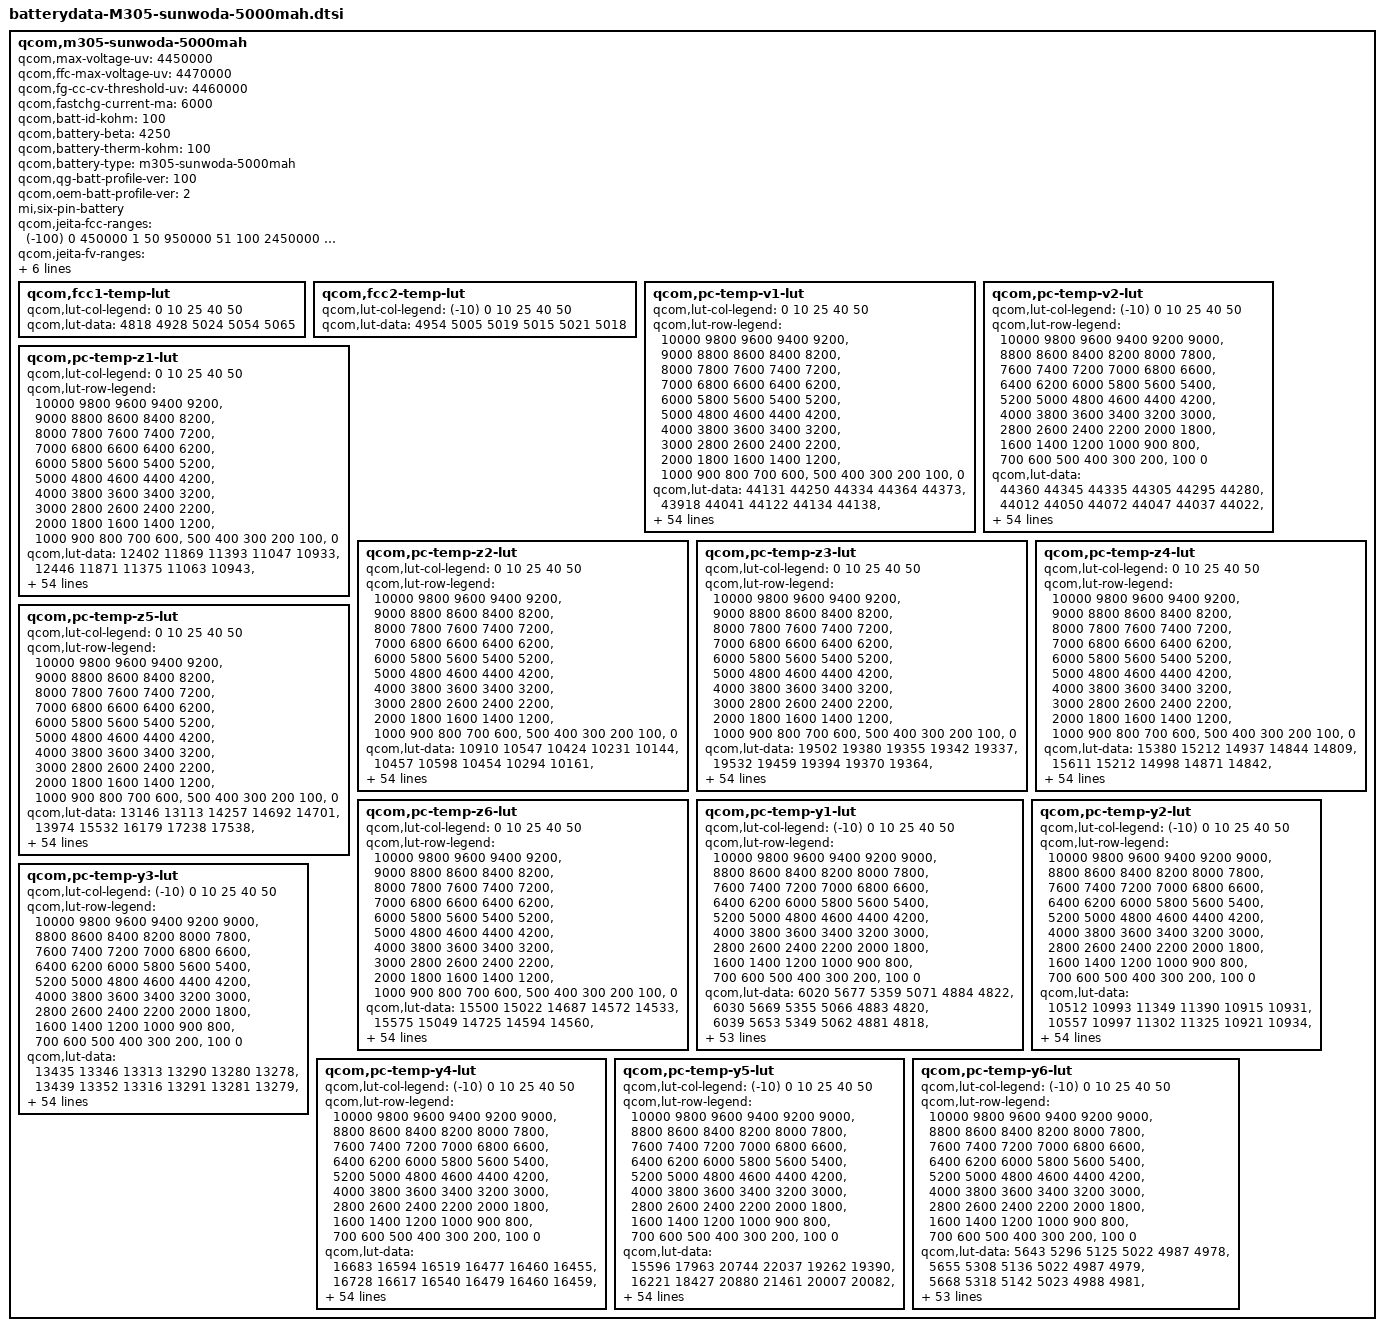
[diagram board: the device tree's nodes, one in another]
/*
 * Copyright (c) 2019, The Linux Foundation. All rights reserved.
 * Copyright (C) 2021 XiaoMi, Inc.
 *
 * This program is free software; you can redistribute it and/or modify
 * it under the terms of the GNU General Public License version 2 and
 * only version 2 as published by the Free Software Foundation.
 *
 * This program is distributed in the hope that it will be useful,
 * but WITHOUT ANY WARRANTY; without even the implied warranty of
 * MERCHANTABILITY or FITNESS FOR A PARTICULAR PURPOSE.  See the
 * GNU General Public License for more details.
 */
/* 4622819_LC_M700_ATL_5160mAH_PM7150B_averaged_Master_May26th2020 */

 qcom,m305-sunwoda-5000mah {
	/* 4916507_LC_M305_5020mAH_PM6150_averaged_MasterSlave_Nov12th2020 */
	qcom,max-voltage-uv = <4450000>;
	qcom,ffc-max-voltage-uv = <4470000>;
	qcom,fg-cc-cv-threshold-uv = <4460000>;
	qcom,fastchg-current-ma = <6000>;
	qcom,batt-id-kohm = <100>;
	qcom,battery-beta = <4250>;
	qcom,battery-therm-kohm = <100>;
	qcom,battery-type = "m305-sunwoda-5000mah";
	qcom,qg-batt-profile-ver = <100>;
	qcom,oem-batt-profile-ver = <2>;
	mi,six-pin-battery;

	qcom,jeita-fcc-ranges = <(-100)  0   450000
                                1   50   950000
				51  100  2450000
				101 150  3900000
				151 480  6000000
				481 580  2450000>;

	qcom,jeita-fv-ranges = <(-100)   0   4450000
                                1   50   4450000
				51  100  4450000
				101 150  4450000
				151 480  4470000
				481 580  4100000>;

	/* COOL = 15 degc, WARM = 48 degC */
	qcom,jeita-soft-thresholds = <0x4621 0x1de6>;
	/* COLD = -10 degC, HOT = 58 degC*/
	qcom,jeita-hard-thresholds = <0x6226 0x15f7>;
	/* COOL hys = 18 degC, WARM hys = 45 degC */
	qcom,jeita-soft-hys-thresholds = <0x4206 0x20b8>;
	qcom,jeita-soft-fcc-ua = <3900000 2450000>;
	qcom,jeita-soft-fv-uv = <4450000 4100000>;

	qcom,fcc1-temp-lut {
		qcom,lut-col-legend = <0 10 25 40 50>;
		qcom,lut-data = <4818 4928 5024 5054 5065>;
	};

	qcom,fcc2-temp-lut {
		qcom,lut-col-legend = <(-10) 0 10 25 40 50>;
		qcom,lut-data = <4954 5005 5019 5015 5021 5018>;
	};

	qcom,pc-temp-v1-lut {
		qcom,lut-col-legend = <0 10 25 40 50>;
		qcom,lut-row-legend = <10000 9800 9600 9400 9200>,
			<9000 8800 8600 8400 8200>,
			<8000 7800 7600 7400 7200>,
			<7000 6800 6600 6400 6200>,
			<6000 5800 5600 5400 5200>,
			<5000 4800 4600 4400 4200>,
			<4000 3800 3600 3400 3200>,
			<3000 2800 2600 2400 2200>,
			<2000 1800 1600 1400 1200>,
			<1000 900 800 700 600>,
			<500 400 300 200 100>,
			<0>;
		qcom,lut-data = <44131 44250 44334 44364 44373>,
			<43918 44041 44122 44134 44138>,
			<43699 43831 43918 43929 43931>,
			<43476 43621 43709 43725 43729>,
			<43246 43406 43495 43515 43519>,
			<43010 43177 43274 43301 43306>,
			<42773 42936 43042 43076 43082>,
			<42533 42693 42801 42837 42844>,
			<42294 42450 42559 42595 42603>,
			<42066 42208 42314 42351 42362>,
			<41848 41973 42071 42108 42121>,
			<41631 41742 41833 41868 41883>,
			<41407 41517 41600 41631 41647>,
			<41183 41294 41371 41399 41415>,
			<40973 41077 41147 41176 41188>,
			<40778 40868 40930 40960 40967>,
			<40589 40665 40722 40750 40754>,
			<40394 40471 40521 40546 40548>,
			<40198 40295 40332 40352 40353>,
			<40015 40122 40161 40179 40178>,
			<39860 39919 39980 40002 40003>,
			<39705 39665 39740 39768 39777>,
			<39498 39423 39466 39480 39497>,
			<39210 39228 39255 39254 39267>,
			<38984 39058 39095 39103 39109>,
			<38875 38930 38960 38975 38978>,
			<38799 38836 38841 38851 38853>,
			<38731 38752 38736 38734 38739>,
			<38671 38664 38637 38628 38633>,
			<38615 38577 38542 38531 38533>,
			<38555 38499 38455 38442 38443>,
			<38495 38428 38380 38365 38361>,
			<38438 38364 38311 38294 38287>,
			<38385 38307 38250 38226 38216>,
			<38337 38256 38197 38161 38147>,
			<38293 38209 38145 38098 38078>,
			<38257 38170 38096 38035 38008>,
			<38213 38128 38045 37973 37936>,
			<38141 38061 37978 37895 37847>,
			<38044 37965 37888 37794 37733>,
			<37934 37855 37782 37681 37608>,
			<37802 37729 37662 37565 37488>,
			<37651 37584 37523 37436 37358>,
			<37473 37406 37355 37263 37186>,
			<37347 37248 37201 37123 37050>,
			<37234 37139 37094 37044 36984>,
			<37193 37107 37066 37011 36953>,
			<37159 37087 37043 36993 36934>,
			<37124 37059 37025 36971 36911>,
			<37075 37018 36977 36910 36839>,
			<36893 36805 36738 36636 36545>,
			<36445 36354 36287 36185 36095>,
			<35858 35760 35697 35598 35506>,
			<35050 34938 34886 34795 34701>,
			<33694 33574 33616 33536 33440>,
			<30000 30000 30000 30000 30000>;
	};

	qcom,pc-temp-v2-lut {
		qcom,lut-col-legend = <(-10) 0 10 25 40 50>;
		qcom,lut-row-legend = <10000 9800 9600 9400 9200 9000>,
			<8800 8600 8400 8200 8000 7800>,
			<7600 7400 7200 7000 6800 6600>,
			<6400 6200 6000 5800 5600 5400>,
			<5200 5000 4800 4600 4400 4200>,
			<4000 3800 3600 3400 3200 3000>,
			<2800 2600 2400 2200 2000 1800>,
			<1600 1400 1200 1000 900 800>,
			<700 600 500 400 300 200>,
			<100 0>;
		qcom,lut-data = <44360 44345 44335 44305 44295 44280>,
			<44012 44050 44072 44047 44037 44022>,
			<43697 43778 43823 43801 43791 43778>,
			<43421 43532 43592 43570 43560 43548>,
			<43181 43313 43379 43355 43345 43335>,
			<42946 43091 43161 43135 43127 43118>,
			<42697 42851 42925 42899 42893 42887>,
			<42448 42606 42681 42657 42652 42648>,
			<42209 42360 42437 42414 42411 42409>,
			<41984 42111 42192 42169 42168 42166>,
			<41756 41867 41949 41927 41927 41925>,
			<41510 41629 41710 41688 41688 41686>,
			<41262 41400 41476 41453 41453 41452>,
			<41049 41183 41245 41222 41223 41222>,
			<40879 40979 41020 40998 40998 40998>,
			<40689 40777 40802 40780 40781 40780>,
			<40395 40578 40596 40571 40573 40572>,
			<40034 40372 40394 40369 40372 40371>,
			<39747 40131 40193 40179 40183 40182>,
			<39530 39844 39993 40002 40006 40005>,
			<39326 39570 39776 39806 39814 39814>,
			<39098 39330 39511 39557 39576 39582>,
			<38868 39110 39241 39295 39329 39341>,
			<38678 38919 39033 39082 39117 39131>,
			<38520 38750 38859 38899 38925 38938>,
			<38390 38596 38706 38742 38764 38775>,
			<38294 38454 38569 38611 38635 38644>,
			<38216 38325 38446 38497 38523 38530>,
			<38146 38210 38334 38390 38418 38423>,
			<38081 38104 38232 38291 38320 38323>,
			<38022 38023 38139 38202 38231 38233>,
			<37961 37967 38051 38121 38154 38155>,
			<37903 37922 37973 38045 38081 38081>,
			<37844 37880 37907 37975 38008 38004>,
			<37786 37842 37850 37909 37934 37926>,
			<37727 37803 37798 37839 37852 37837>,
			<37664 37764 37754 37761 37754 37724>,
			<37598 37721 37710 37679 37649 37606>,
			<37524 37656 37649 37596 37555 37508>,
			<37441 37560 37572 37512 37465 37422>,
			<37348 37446 37478 37422 37370 37331>,
			<37241 37316 37356 37321 37271 37230>,
			<37119 37167 37215 37206 37156 37113>,
			<37007 36995 37053 37062 37009 36958>,
			<36902 36848 36904 36934 36895 36844>,
			<36804 36748 36825 36877 36853 36803>,
			<36756 36716 36792 36859 36843 36792>,
			<36713 36675 36760 36842 36828 36777>,
			<36664 36629 36711 36816 36802 36749>,
			<36611 36552 36622 36746 36718 36653>,
			<36516 36338 36378 36508 36433 36333>,
			<36303 35908 35872 36014 35933 35828>,
			<35864 35265 35199 35382 35289 35175>,
			<35165 34309 34285 34531 34406 34275>,
			<34164 32747 32829 33216 33099 32945>,
			<32424 29203 28284 28221 28318 28327>;
	};

	qcom,pc-temp-z1-lut {
		qcom,lut-col-legend = <0 10 25 40 50>;
		qcom,lut-row-legend = <10000 9800 9600 9400 9200>,
			<9000 8800 8600 8400 8200>,
			<8000 7800 7600 7400 7200>,
			<7000 6800 6600 6400 6200>,
			<6000 5800 5600 5400 5200>,
			<5000 4800 4600 4400 4200>,
			<4000 3800 3600 3400 3200>,
			<3000 2800 2600 2400 2200>,
			<2000 1800 1600 1400 1200>,
			<1000 900 800 700 600>,
			<500 400 300 200 100>,
			<0>;
		qcom,lut-data = <12402 11869 11393 11047 10933>,
			<12446 11871 11375 11063 10943>,
			<12427 11868 11368 11056 10939>,
			<12400 11859 11361 11048 10934>,
			<12383 11847 11353 11042 10930>,
			<12366 11834 11345 11035 10926>,
			<12350 11819 11335 11029 10923>,
			<12327 11803 11321 11022 10920>,
			<12302 11787 11310 11017 10917>,
			<12293 11772 11303 11014 10915>,
			<12292 11762 11297 11011 10914>,
			<12289 11753 11292 11009 10913>,
			<12269 11748 11288 11007 10912>,
			<12235 11746 11286 11006 10912>,
			<12224 11744 11284 11005 10911>,
			<12224 11743 11283 11005 10911>,
			<12224 11739 11283 11005 10911>,
			<12218 11735 11285 11005 10912>,
			<12200 11729 11286 11005 10913>,
			<12190 11723 11288 11006 10914>,
			<12197 11721 11290 11008 10916>,
			<12209 11724 11291 11008 10917>,
			<12213 11728 11292 11008 10918>,
			<12222 11729 11293 11009 10919>,
			<12226 11731 11298 11012 10921>,
			<12222 11733 11304 11016 10923>,
			<12217 11740 11310 11020 10926>,
			<12214 11746 11317 11023 10929>,
			<12214 11747 11322 11027 10932>,
			<12216 11747 11326 11031 10936>,
			<12223 11749 11329 11035 10939>,
			<12231 11756 11333 11038 10942>,
			<12237 11764 11338 11040 10945>,
			<12247 11767 11342 11044 10948>,
			<12256 11769 11346 11049 10952>,
			<12256 11772 11350 11054 10957>,
			<12250 11776 11357 11059 10960>,
			<12246 11780 11366 11064 10964>,
			<12257 11788 11375 11069 10967>,
			<12278 11801 11385 11073 10971>,
			<12292 11809 11394 11078 10974>,
			<12300 11812 11399 11083 10978>,
			<12310 11816 11403 11088 10982>,
			<12328 11834 11411 11091 10984>,
			<12348 11847 11428 11097 10986>,
			<12364 11859 11427 11099 10987>,
			<12358 11862 11430 11101 10987>,
			<12356 11840 11430 11103 10988>,
			<12351 11842 11436 11104 10990>,
			<12345 11856 11440 11110 10993>,
			<12380 11867 11456 11114 10997>,
			<12406 11879 11461 11121 11002>,
			<12406 11890 11471 11130 11010>,
			<12425 11914 11488 11142 11022>,
			<12425 11914 11488 11142 11022>,
			<12425 11914 11488 11142 11022>;
	};

	qcom,pc-temp-z2-lut {
		qcom,lut-col-legend = <0 10 25 40 50>;
		qcom,lut-row-legend = <10000 9800 9600 9400 9200>,
			<9000 8800 8600 8400 8200>,
			<8000 7800 7600 7400 7200>,
			<7000 6800 6600 6400 6200>,
			<6000 5800 5600 5400 5200>,
			<5000 4800 4600 4400 4200>,
			<4000 3800 3600 3400 3200>,
			<3000 2800 2600 2400 2200>,
			<2000 1800 1600 1400 1200>,
			<1000 900 800 700 600>,
			<500 400 300 200 100>,
			<0>;
		qcom,lut-data = <10910 10547 10424 10231 10144>,
			<10457 10598 10454 10294 10161>,
			<10447 10612 10524 10333 10214>,
			<10431 10587 10540 10354 10236>,
			<10411 10549 10514 10345 10225>,
			<10377 10521 10480 10322 10196>,
			<10348 10489 10445 10300 10185>,
			<10326 10461 10405 10270 10184>,
			<10309 10437 10387 10248 10180>,
			<10329 10417 10380 10236 10136>,
			<10450 10405 10377 10228 10067>,
			<10535 10397 10376 10228 10052>,
			<10470 10393 10372 10235 10057>,
			<10349 10410 10373 10237 10066>,
			<10319 10442 10380 10212 10079>,
			<10341 10462 10388 10175 10096>,
			<10371 10475 10393 10162 10103>,
			<10396 10487 10397 10154 10105>,
			<10421 10500 10403 10154 10108>,
			<10439 10514 10409 10166 10130>,
			<10453 10533 10420 10191 10163>,
			<10463 10565 10475 10272 10194>,
			<10463 10586 10573 10451 10239>,
			<10455 10562 10594 10522 10278>,
			<10449 10511 10519 10398 10426>,
			<10456 10498 10455 10264 10602>,
			<10469 10519 10474 10292 10581>,
			<10478 10540 10516 10396 10420>,
			<10483 10545 10527 10434 10286>,
			<10488 10547 10516 10368 10183>,
			<10496 10548 10501 10278 10104>,
			<10505 10547 10483 10213 10077>,
			<10512 10547 10464 10155 10061>,
			<10517 10550 10461 10140 10058>,
			<10522 10560 10474 10153 10078>,
			<10526 10570 10494 10173 10111>,
			<10532 10580 10519 10203 10158>,
			<10540 10590 10550 10251 10221>,
			<10552 10602 10575 10300 10263>,
			<10566 10617 10595 10355 10293>,
			<10569 10626 10612 10395 10309>,
			<10560 10628 10629 10402 10299>,
			<10560 10631 10641 10404 10283>,
			<10596 10643 10631 10451 10310>,
			<10428 10750 10644 10433 10314>,
			<10558 10817 10660 10355 10251>,
			<10661 10800 10650 10343 10246>,
			<10832 10817 10625 10391 10285>,
			<10766 10811 10628 10391 10309>,
			<12908 10884 10655 10437 10362>,
			<13525 10944 10706 10371 10269>,
			<10574 10997 10600 10230 10116>,
			<10307 10938 10577 10181 10065>,
			<10025 10788 10504 10134 10018>,
			<10025 10788 10504 10134 10018>,
			<10025 10788 10504 10134 10018>;
	};

	qcom,pc-temp-z3-lut {
		qcom,lut-col-legend = <0 10 25 40 50>;
		qcom,lut-row-legend = <10000 9800 9600 9400 9200>,
			<9000 8800 8600 8400 8200>,
			<8000 7800 7600 7400 7200>,
			<7000 6800 6600 6400 6200>,
			<6000 5800 5600 5400 5200>,
			<5000 4800 4600 4400 4200>,
			<4000 3800 3600 3400 3200>,
			<3000 2800 2600 2400 2200>,
			<2000 1800 1600 1400 1200>,
			<1000 900 800 700 600>,
			<500 400 300 200 100>,
			<0>;
		qcom,lut-data = <19502 19380 19355 19342 19337>,
			<19532 19459 19394 19370 19364>,
			<19592 19499 19414 19385 19375>,
			<19646 19513 19426 19395 19383>,
			<19665 19521 19435 19401 19389>,
			<19678 19530 19441 19405 19394>,
			<19684 19539 19443 19409 19399>,
			<19685 19543 19444 19413 19403>,
			<19685 19542 19444 19415 19405>,
			<19684 19539 19442 19413 19403>,
			<19683 19536 19440 19409 19398>,
			<19681 19529 19436 19406 19394>,
			<19673 19522 19429 19404 19391>,
			<19660 19516 19425 19401 19389>,
			<19651 19510 19422 19396 19386>,
			<19644 19507 19420 19391 19384>,
			<19636 19505 19417 19388 19381>,
			<19627 19503 19414 19385 19378>,
			<19618 19497 19411 19382 19375>,
			<19613 19490 19408 19377 19369>,
			<19612 19490 19405 19372 19364>,
			<19612 19507 19412 19375 19364>,
			<19615 19520 19426 19387 19368>,
			<19625 19513 19429 19391 19371>,
			<19631 19498 19413 19382 19379>,
			<19627 19493 19400 19371 19390>,
			<19619 19494 19405 19380 19398>,
			<19613 19495 19418 19408 19409>,
			<19608 19500 19428 19419 19413>,
			<19606 19509 19436 19416 19409>,
			<19606 19512 19440 19411 19401>,
			<19607 19510 19438 19404 19394>,
			<19608 19508 19433 19395 19386>,
			<19606 19505 19428 19387 19378>,
			<19604 19500 19422 19381 19369>,
			<19602 19495 19417 19375 19361>,
			<19598 19491 19413 19370 19355>,
			<19593 19488 19409 19365 19349>,
			<19588 19484 19406 19364 19348>,
			<19583 19480 19403 19364 19350>,
			<19577 19476 19400 19364 19353>,
			<19572 19471 19398 19365 19355>,
			<19565 19465 19396 19365 19358>,
			<19551 19461 19392 19370 19363>,
			<19320 19436 19383 19369 19364>,
			<19261 19424 19377 19354 19353>,
			<19261 19421 19372 19353 19351>,
			<19260 19410 19370 19343 19338>,
			<19261 19409 19359 19339 19333>,
			<19257 19392 19355 19336 19330>,
			<19259 19393 19354 19354 19345>,
			<19260 19370 19372 19366 19355>,
			<19262 19347 19368 19366 19356>,
			<19266 19338 19367 19361 19355>,
			<19266 19338 19367 19361 19355>,
			<19266 19338 19367 19361 19355>;
	};

	qcom,pc-temp-z4-lut {
		qcom,lut-col-legend = <0 10 25 40 50>;
		qcom,lut-row-legend = <10000 9800 9600 9400 9200>,
			<9000 8800 8600 8400 8200>,
			<8000 7800 7600 7400 7200>,
			<7000 6800 6600 6400 6200>,
			<6000 5800 5600 5400 5200>,
			<5000 4800 4600 4400 4200>,
			<4000 3800 3600 3400 3200>,
			<3000 2800 2600 2400 2200>,
			<2000 1800 1600 1400 1200>,
			<1000 900 800 700 600>,
			<500 400 300 200 100>,
			<0>;
		qcom,lut-data = <15380 15212 14937 14844 14809>,
			<15611 15212 14998 14871 14842>,
			<15527 15210 14961 14853 14832>,
			<15404 15143 14922 14830 14816>,
			<15300 15040 14881 14808 14799>,
			<15195 14973 14842 14784 14778>,
			<15107 14919 14813 14763 14759>,
			<15041 14875 14788 14744 14742>,
			<14983 14841 14766 14728 14729>,
			<14927 14813 14742 14717 14721>,
			<14866 14790 14726 14708 14716>,
			<14827 14771 14720 14702 14712>,
			<14816 14756 14717 14699 14708>,
			<14809 14747 14714 14695 14705>,
			<14800 14739 14710 14692 14702>,
			<14781 14736 14705 14690 14699>,
			<14766 14734 14702 14686 14696>,
			<14769 14733 14699 14683 14693>,
			<14780 14730 14696 14679 14690>,
			<14786 14728 14693 14673 14683>,
			<14774 14730 14690 14669 14677>,
			<14758 14757 14710 14686 14691>,
			<14770 14790 14759 14744 14754>,
			<14847 14822 14790 14777 14787>,
			<14902 14854 14811 14784 14774>,
			<14899 14861 14822 14788 14752>,
			<14890 14842 14810 14773 14733>,
			<14879 14818 14781 14728 14708>,
			<14862 14799 14758 14704 14695>,
			<14845 14781 14740 14698 14691>,
			<14831 14770 14727 14694 14689>,
			<14818 14765 14723 14691 14685>,
			<14809 14761 14720 14688 14681>,
			<14803 14760 14718 14686 14677>,
			<14798 14758 14717 14684 14673>,
			<14791 14757 14717 14682 14671>,
			<14784 14753 14716 14682 14670>,
			<14777 14748 14715 14682 14670>,
			<14771 14745 14715 14684 14671>,
			<14764 14742 14716 14693 14685>,
			<14756 14737 14717 14700 14696>,
			<14743 14724 14710 14694 14692>,
			<14727 14709 14697 14686 14684>,
			<14709 14697 14691 14686 14689>,
			<14868 14673 14674 14676 14681>,
			<14910 14657 14657 14659 14654>,
			<14907 14652 14652 14654 14646>,
			<14899 14652 14642 14648 14644>,
			<14895 14645 14637 14633 14628>,
			<14889 14659 14636 14626 14621>,
			<14887 14663 14655 14647 14658>,
			<14897 14694 14647 14652 14666>,
			<14901 14724 14652 14657 14673>,
			<14908 14740 14656 14665 14677>,
			<14908 14740 14656 14665 14677>,
			<14908 14740 14656 14665 14677>;
	};

	qcom,pc-temp-z5-lut {
		qcom,lut-col-legend = <0 10 25 40 50>;
		qcom,lut-row-legend = <10000 9800 9600 9400 9200>,
			<9000 8800 8600 8400 8200>,
			<8000 7800 7600 7400 7200>,
			<7000 6800 6600 6400 6200>,
			<6000 5800 5600 5400 5200>,
			<5000 4800 4600 4400 4200>,
			<4000 3800 3600 3400 3200>,
			<3000 2800 2600 2400 2200>,
			<2000 1800 1600 1400 1200>,
			<1000 900 800 700 600>,
			<500 400 300 200 100>,
			<0>;
		qcom,lut-data = <13146 13113 14257 14692 14701>,
			<13974 15532 16179 17238 17538>,
			<15120 17024 17449 18893 19350>,
			<16293 17691 18404 20072 20777>,
			<17166 18228 19154 20890 21999>,
			<17902 19097 19785 21553 23087>,
			<18687 20300 20332 22407 24501>,
			<19688 21493 20813 23816 26565>,
			<20791 22611 21512 25207 28061>,
			<21833 23652 22993 26231 28492>,
			<22853 24454 24150 27149 28756>,
			<23970 25073 24088 28056 29076>,
			<25331 25746 23800 29027 29565>,
			<26952 26635 23746 29433 30196>,
			<28677 27692 24360 29192 31052>,
			<31089 28954 25184 28893 32125>,
			<32869 30699 25816 29183 33289>,
			<32791 31679 26446 30515 34618>,
			<32124 30830 27032 31502 35765>,
			<31781 29326 27532 31701 36815>,
			<32808 30564 28263 31832 37714>,
			<35022 42466 31586 33460 37824>,
			<38728 52014 37290 37409 36624>,
			<46358 46323 37976 38653 35037>,
			<51225 33830 28701 29483 29984>,
			<47954 28682 20864 19529 24811>,
			<41138 27334 21110 20561 25711>,
			<37376 26718 22392 26002 30270>,
			<35458 28130 24295 29388 33158>,
			<34419 32040 28194 31071 34361>,
			<34941 35311 31931 32030 35024>,
			<36860 37945 34046 31588 34787>,
			<38711 39981 35658 30408 33797>,
			<40447 41109 36718 30050 32627>,
			<41856 41930 37559 30649 30922>,
			<42243 42162 37976 31198 29537>,
			<42350 41723 37941 31152 29173>,
			<42464 41007 37788 30992 28979>,
			<42849 40330 37344 30919 29039>,
			<43341 39517 35514 31062 29681>,
			<43324 38601 33638 31139 30222>,
			<41943 37201 32571 30067 30222>,
			<40566 36344 31702 28701 30192>,
			<39575 36754 30637 33002 34470>,
			<17474 36662 31477 34632 37864>,
			<11813 36811 32360 26505 29810>,
			<11750 35238 29767 25499 27492>,
			<11683 28405 31113 22823 22305>,
			<11674 29709 27213 26545 26852>,
			<11669 22635 25956 28360 32036>,
			<11712 22254 21443 30175 27224>,
			<11673 17844 25699 27737 23043>,
			<11598 14723 22269 23763 20038>,
			<11912 14229 20599 19088 17123>,
			<11912 14229 20599 19088 17123>,
			<11912 14229 20599 19088 17123>;
	};

	qcom,pc-temp-z6-lut {
		qcom,lut-col-legend = <0 10 25 40 50>;
		qcom,lut-row-legend = <10000 9800 9600 9400 9200>,
			<9000 8800 8600 8400 8200>,
			<8000 7800 7600 7400 7200>,
			<7000 6800 6600 6400 6200>,
			<6000 5800 5600 5400 5200>,
			<5000 4800 4600 4400 4200>,
			<4000 3800 3600 3400 3200>,
			<3000 2800 2600 2400 2200>,
			<2000 1800 1600 1400 1200>,
			<1000 900 800 700 600>,
			<500 400 300 200 100>,
			<0>;
		qcom,lut-data = <15500 15022 14687 14572 14533>,
			<15575 15049 14725 14594 14560>,
			<15534 15053 14718 14592 14560>,
			<15470 15019 14709 14590 14560>,
			<15411 14965 14694 14584 14556>,
			<15347 14930 14676 14574 14549>,
			<15288 14900 14661 14567 14543>,
			<15240 14874 14648 14560 14539>,
			<15197 14851 14636 14554 14534>,
			<15157 14829 14624 14547 14528>,
			<15119 14810 14614 14541 14523>,
			<15089 14793 14607 14536 14519>,
			<15067 14779 14602 14533 14516>,
			<15049 14770 14598 14529 14513>,
			<15031 14762 14594 14525 14510>,
			<15011 14758 14591 14521 14507>,
			<14996 14755 14588 14517 14504>,
			<14992 14752 14585 14514 14501>,
			<14990 14748 14582 14511 14498>,
			<14988 14743 14579 14505 14492>,
			<14984 14745 14577 14501 14487>,
			<14979 14765 14590 14511 14493>,
			<14986 14787 14620 14543 14522>,
			<15024 14797 14632 14558 14537>,
			<15051 14804 14634 14556 14536>,
			<15049 14806 14634 14554 14535>,
			<15043 14799 14632 14552 14533>,
			<15036 14792 14628 14549 14529>,
			<15029 14788 14625 14546 14525>,
			<15022 14786 14623 14543 14521>,
			<15017 14784 14621 14539 14517>,
			<15014 14782 14618 14534 14512>,
			<15012 14780 14615 14528 14506>,
			<15011 14779 14612 14524 14501>,
			<15010 14777 14610 14520 14495>,
			<15008 14776 14608 14517 14489>,
			<15007 14775 14607 14514 14486>,
			<15007 14773 14606 14512 14483>,
			<15008 14774 14606 14512 14483>,
			<15011 14775 14606 14517 14490>,
			<15012 14775 14607 14521 14496>,
			<15013 14772 14605 14519 14496>,
			<15013 14769 14601 14516 14494>,
			<15012 14768 14598 14520 14499>,
			<14984 14755 14589 14515 14497>,
			<14977 14746 14581 14501 14480>,
			<14975 14743 14577 14498 14476>,
			<14974 14738 14573 14491 14468>,
			<14974 14737 14566 14482 14459>,
			<14976 14738 14565 14478 14454>,
			<14984 14747 14576 14497 14478>,
			<14997 14754 14585 14508 14490>,
			<15010 14762 14588 14513 14496>,
			<15032 14774 14594 14517 14501>,
			<15032 14774 14594 14517 14501>,
			<15032 14774 14594 14517 14501>;
	};

	qcom,pc-temp-y1-lut {
		qcom,lut-col-legend = <(-10) 0 10 25 40 50>;
		qcom,lut-row-legend = <10000 9800 9600 9400 9200 9000>,
			<8800 8600 8400 8200 8000 7800>,
			<7600 7400 7200 7000 6800 6600>,
			<6400 6200 6000 5800 5600 5400>,
			<5200 5000 4800 4600 4400 4200>,
			<4000 3800 3600 3400 3200 3000>,
			<2800 2600 2400 2200 2000 1800>,
			<1600 1400 1200 1000 900 800>,
			<700 600 500 400 300 200>,
			<100 0>;
		qcom,lut-data = <6020 5677 5359 5071 4884 4822>,
			<6030 5669 5355 5066 4883 4820>,
			<6039 5653 5349 5062 4881 4818>,
			<6047 5634 5342 5058 4880 4816>,
			<6053 5619 5337 5054 4878 4815>,
			<6055 5612 5334 5051 4876 4813>,
			<6053 5612 5334 5048 4874 4812>,
			<6050 5613 5334 5045 4872 4811>,
			<6049 5614 5334 5042 4870 4810>,
			<6055 5620 5333 5038 4869 4809>,
			<6062 5624 5332 5036 4868 4809>,
			<6071 5619 5333 5035 4867 4808>,
			<6084 5610 5333 5035 4865 4808>,
			<6086 5607 5329 5035 4865 4808>,
			<6069 5605 5318 5033 4865 4807>,
			<6055 5605 5312 5032 4865 4807>,
			<6058 5607 5312 5032 4865 4808>,
			<6066 5612 5314 5032 4865 4810>,
			<6070 5618 5315 5032 4865 4810>,
			<6074 5625 5317 5034 4866 4810>,
			<6079 5630 5319 5036 4867 4811>,
			<6088 5632 5319 5038 4868 4811>,
			<6099 5632 5319 5040 4869 4812>,
			<6102 5631 5319 5043 4870 4813>,
			<6092 5627 5320 5046 4872 4815>,
			<6083 5624 5322 5051 4874 4817>,
			<6088 5626 5325 5056 4876 4819>,
			<6095 5627 5329 5061 4878 4820>,
			<6097 5628 5336 5064 4880 4822>,
			<6105 5628 5346 5065 4883 4825>,
			<6115 5628 5351 5068 4886 4827>,
			<6118 5636 5349 5073 4889 4829>,
			<6118 5647 5347 5080 4892 4831>,
			<6118 5647 5346 5083 4895 4832>,
			<6114 5642 5346 5086 4898 4833>,
			<6108 5639 5346 5088 4900 4834>,
			<6106 5643 5349 5092 4902 4836>,
			<6104 5648 5353 5097 4903 4839>,
			<6102 5650 5357 5099 4905 4840>,
			<6092 5651 5361 5101 4906 4841>,
			<6081 5650 5367 5103 4908 4842>,
			<6084 5659 5383 5107 4910 4844>,
			<6098 5667 5393 5109 4911 4846>,
			<6108 5660 5392 5115 4913 4848>,
			<6118 5661 5384 5127 4916 4849>,
			<6122 5659 5395 5130 4919 4851>,
			<6118 5675 5389 5126 4918 4851>,
			<6126 5685 5402 5134 4919 4852>,
			<6142 5669 5408 5135 4920 4853>,
			<6189 5699 5418 5132 4921 4853>,
			<6196 5694 5419 5135 4922 4854>,
			<6242 5749 5415 5139 4924 4857>,
			<6318 5783 5433 5152 4929 4861>,
			<6376 5849 5476 5176 4937 4869>,
			<6376 5849 5476 5176 4937 4869>,
			<6376 5849 5476 5176 4937 4869>;
	};

	qcom,pc-temp-y2-lut {
		qcom,lut-col-legend = <(-10) 0 10 25 40 50>;
		qcom,lut-row-legend = <10000 9800 9600 9400 9200 9000>,
			<8800 8600 8400 8200 8000 7800>,
			<7600 7400 7200 7000 6800 6600>,
			<6400 6200 6000 5800 5600 5400>,
			<5200 5000 4800 4600 4400 4200>,
			<4000 3800 3600 3400 3200 3000>,
			<2800 2600 2400 2200 2000 1800>,
			<1600 1400 1200 1000 900 800>,
			<700 600 500 400 300 200>,
			<100 0>;
		qcom,lut-data = <10512 10993 11349 11390 10915 10931>,
			<10557 10997 11302 11325 10921 10934>,
			<10602 10997 11257 11262 10918 10917>,
			<10643 10993 11214 11203 10907 10887>,
			<10680 10985 11175 11148 10892 10854>,
			<10708 10976 11138 11099 10874 10825>,
			<10730 10960 11104 11049 10846 10788>,
			<10747 10943 11073 11007 10814 10750>,
			<10754 10938 11048 10991 10800 10739>,
			<10753 10940 11023 10982 10791 10736>,
			<10755 10945 11013 10976 10782 10732>,
			<10820 10957 11017 10971 10755 10718>,
			<10929 10978 11027 10966 10724 10701>,
			<10951 11016 11042 10963 10718 10700>,
			<10896 11099 11074 10961 10726 10705>,
			<10851 11146 11115 10964 10739 10708>,
			<10885 11136 11168 10994 10765 10702>,
			<10956 11122 11231 11047 10806 10692>,
			<10977 11130 11301 11113 10853 10698>,
			<10972 11179 11384 11209 10915 10731>,
			<10961 11210 11421 11256 10971 10771>,
			<10677 11208 11372 11247 11031 10847>,
			<10043 11206 11306 11237 11079 10929>,
			<9787 11207 11306 11240 11072 10944>,
			<9747 11214 11344 11259 11025 10932>,
			<9725 11217 11370 11270 11002 10927>,
			<9713 11213 11378 11278 11030 10960>,
			<9704 11207 11385 11291 11073 10999>,
			<9698 11210 11398 11306 11103 11011>,
			<9692 11228 11419 11328 11131 11034>,
			<9688 11239 11428 11356 11149 11049>,
			<9684 11216 11422 11401 11164 11080>,
			<9681 11169 11412 11448 11177 11115>,
			<9678 11126 11403 11464 11187 11123>,
			<9676 11080 11391 11465 11204 11133>,
			<9674 11025 11374 11459 11209 11136>,
			<9672 10968 11346 11440 11187 11123>,
			<9670 10891 11309 11417 11158 11104>,
			<9669 10675 11271 11402 11139 11085>,
			<9668 10131 11226 11384 11114 11051>,
			<9667 9784 11165 11366 11105 11030>,
			<9666 9727 11062 11350 11121 11021>,
			<9665 9699 10942 11332 11127 11006>,
			<9664 9686 10816 11311 11081 10958>,
			<9663 9677 10655 11216 11037 10877>,
			<9661 9671 10574 11210 10948 10797>,
			<9660 9670 10366 11161 10942 10765>,
			<9659 9666 10215 11151 10945 10767>,
			<9658 9664 10028 11187 10967 10774>,
			<9656 9662 9891 11203 10936 10780>,
			<9652 9658 9768 11190 10901 10759>,
			<9650 9654 9695 11079 10842 10694>,
			<9649 9650 9668 10994 10772 10612>,
			<9648 9649 9656 10901 10633 10460>,
			<9648 9649 9656 10901 10633 10460>,
			<9648 9649 9656 10901 10633 10460>;
	};

	qcom,pc-temp-y3-lut {
		qcom,lut-col-legend = <(-10) 0 10 25 40 50>;
		qcom,lut-row-legend = <10000 9800 9600 9400 9200 9000>,
			<8800 8600 8400 8200 8000 7800>,
			<7600 7400 7200 7000 6800 6600>,
			<6400 6200 6000 5800 5600 5400>,
			<5200 5000 4800 4600 4400 4200>,
			<4000 3800 3600 3400 3200 3000>,
			<2800 2600 2400 2200 2000 1800>,
			<1600 1400 1200 1000 900 800>,
			<700 600 500 400 300 200>,
			<100 0>;
		qcom,lut-data = <13435 13346 13313 13290 13280 13278>,
			<13439 13352 13316 13291 13281 13279>,
			<13446 13358 13319 13292 13282 13280>,
			<13453 13364 13322 13292 13283 13281>,
			<13458 13369 13324 13293 13284 13282>,
			<13461 13373 13326 13294 13285 13282>,
			<13462 13375 13327 13295 13285 13283>,
			<13463 13377 13328 13295 13285 13284>,
			<13463 13379 13329 13296 13286 13284>,
			<13465 13380 13330 13296 13287 13285>,
			<13465 13381 13332 13297 13288 13286>,
			<13456 13380 13334 13297 13288 13286>,
			<13438 13377 13335 13298 13288 13287>,
			<13431 13374 13335 13298 13289 13288>,
			<13429 13369 13334 13299 13289 13288>,
			<13427 13365 13333 13299 13289 13288>,
			<13422 13364 13329 13300 13291 13290>,
			<13414 13362 13324 13302 13293 13291>,
			<13407 13360 13324 13302 13294 13292>,
			<13401 13354 13325 13301 13295 13292>,
			<13396 13348 13326 13299 13295 13292>,
			<13387 13344 13321 13297 13293 13290>,
			<13376 13339 13315 13295 13288 13286>,
			<13371 13336 13312 13293 13285 13284>,
			<13369 13334 13310 13291 13282 13281>,
			<13369 13331 13309 13290 13281 13280>,
			<13370 13329 13308 13289 13281 13280>,
			<13376 13327 13306 13289 13282 13281>,
			<13384 13324 13305 13289 13281 13281>,
			<13397 13318 13304 13288 13280 13279>,
			<13414 13315 13304 13288 13280 13279>,
			<13430 13317 13304 13288 13280 13279>,
			<13447 13322 13304 13288 13280 13279>,
			<13469 13326 13304 13288 13281 13280>,
			<13497 13330 13304 13288 13281 13281>,
			<13531 13334 13304 13288 13282 13282>,
			<13569 13338 13305 13287 13282 13281>,
			<13614 13343 13307 13287 13281 13280>,
			<13662 13349 13308 13287 13281 13280>,
			<13713 13359 13310 13287 13282 13281>,
			<13769 13372 13311 13287 13282 13282>,
			<13830 13386 13313 13288 13283 13282>,
			<13899 13406 13315 13288 13283 13282>,
			<13981 13437 13317 13289 13281 13279>,
			<14087 13490 13322 13289 13280 13279>,
			<14215 13535 13326 13291 13286 13284>,
			<14265 13594 13329 13293 13289 13286>,
			<14397 13669 13336 13296 13290 13288>,
			<14559 13778 13346 13300 13292 13289>,
			<14870 13939 13367 13303 13291 13288>,
			<15768 14207 13399 13300 13287 13284>,
			<17873 14934 13457 13299 13287 13284>,
			<23624 17723 13642 13306 13290 13288>,
			<45215 29308 14430 13315 13298 13296>,
			<45215 29308 14430 13315 13298 13296>,
			<45215 29308 14430 13315 13298 13296>;
	};

	qcom,pc-temp-y4-lut {
		qcom,lut-col-legend = <(-10) 0 10 25 40 50>;
		qcom,lut-row-legend = <10000 9800 9600 9400 9200 9000>,
			<8800 8600 8400 8200 8000 7800>,
			<7600 7400 7200 7000 6800 6600>,
			<6400 6200 6000 5800 5600 5400>,
			<5200 5000 4800 4600 4400 4200>,
			<4000 3800 3600 3400 3200 3000>,
			<2800 2600 2400 2200 2000 1800>,
			<1600 1400 1200 1000 900 800>,
			<700 600 500 400 300 200>,
			<100 0>;
		qcom,lut-data = <16683 16594 16519 16477 16460 16455>,
			<16728 16617 16540 16479 16460 16459>,
			<16796 16657 16563 16481 16460 16461>,
			<16870 16702 16583 16482 16461 16464>,
			<16933 16739 16598 16484 16461 16465>,
			<16965 16754 16603 16484 16461 16465>,
			<16972 16752 16599 16484 16461 16465>,
			<16976 16749 16593 16483 16461 16464>,
			<16983 16746 16589 16483 16461 16463>,
			<16997 16743 16587 16485 16462 16463>,
			<17014 16742 16586 16487 16463 16463>,
			<17035 16751 16588 16490 16464 16463>,
			<17062 16773 16594 16494 16467 16464>,
			<17091 16803 16602 16500 16470 16465>,
			<17132 16857 16618 16507 16475 16467>,
			<17158 16893 16639 16517 16479 16470>,
			<17081 16904 16682 16527 16483 16473>,
			<16911 16911 16726 16541 16488 16477>,
			<16828 16895 16732 16565 16500 16486>,
			<16800 16807 16727 16606 16526 16505>,
			<16778 16724 16718 16627 16538 16515>,
			<16752 16675 16662 16594 16529 16511>,
			<16726 16638 16585 16541 16512 16503>,
			<16705 16611 16550 16508 16494 16491>,
			<16683 16590 16530 16484 16471 16470>,
			<16670 16572 16519 16474 16460 16459>,
			<16671 16553 16514 16474 16461 16458>,
			<16677 16535 16510 16475 16461 16458>,
			<16681 16526 16509 16477 16463 16459>,
			<16683 16518 16507 16481 16469 16464>,
			<16685 16515 16506 16486 16476 16471>,
			<16689 16519 16500 16491 16485 16478>,
			<16696 16525 16494 16497 16494 16486>,
			<16703 16535 16494 16500 16498 16493>,
			<16710 16551 16495 16502 16502 16500>,
			<16716 16570 16498 16503 16502 16502>,
			<16722 16592 16509 16492 16490 16491>,
			<16729 16616 16526 16478 16477 16477>,
			<16731 16631 16536 16473 16475 16477>,
			<16729 16643 16545 16471 16475 16486>,
			<16726 16648 16551 16470 16476 16494>,
			<16720 16646 16554 16479 16480 16500>,
			<16711 16641 16557 16484 16482 16501>,
			<16710 16629 16562 16479 16457 16462>,
			<16711 16619 16561 16477 16445 16445>,
			<16723 16618 16551 16474 16458 16475>,
			<16718 16626 16566 16487 16491 16514>,
			<16726 16646 16588 16511 16528 16552>,
			<16748 16673 16617 16548 16564 16585>,
			<16785 16707 16658 16575 16569 16580>,
			<16958 16732 16679 16550 16505 16501>,
			<17324 16788 16685 16514 16475 16482>,
			<18456 17516 16736 16536 16477 16481>,
			<25282 23793 17011 16576 16485 16484>,
			<25282 23793 17011 16576 16485 16484>,
			<25282 23793 17011 16576 16485 16484>;
	};

	qcom,pc-temp-y5-lut {
		qcom,lut-col-legend = <(-10) 0 10 25 40 50>;
		qcom,lut-row-legend = <10000 9800 9600 9400 9200 9000>,
			<8800 8600 8400 8200 8000 7800>,
			<7600 7400 7200 7000 6800 6600>,
			<6400 6200 6000 5800 5600 5400>,
			<5200 5000 4800 4600 4400 4200>,
			<4000 3800 3600 3400 3200 3000>,
			<2800 2600 2400 2200 2000 1800>,
			<1600 1400 1200 1000 900 800>,
			<700 600 500 400 300 200>,
			<100 0>;
		qcom,lut-data = <15596 17963 20744 22037 19262 19390>,
			<16221 18427 20880 21461 20007 20082>,
			<16984 19000 20897 20895 20389 20627>,
			<17753 19563 20820 20353 20494 21027>,
			<18398 19996 20680 19846 20410 21285>,
			<18790 20179 20503 19387 20221 21406>,
			<18959 20154 20254 18983 19705 21318>,
			<19068 20065 19944 18599 19032 21136>,
			<19190 19904 19651 18182 18725 21034>,
			<19550 19474 19348 17729 18567 20729>,
			<19796 18968 19002 17275 18380 20432>,
			<19057 18429 18566 16835 17950 20173>,
			<17690 17873 18035 16398 17352 19828>,
			<17684 17428 17356 15934 16767 19351>,
			<20602 17001 16431 15415 16102 18643>,
			<22983 16809 15985 15075 15800 18200>,
			<22623 18940 16053 14906 15978 18112>,
			<21765 22236 16233 14797 16217 18056>,
			<21570 23074 17318 14856 16148 17715>,
			<22214 23156 21083 15291 15734 16629>,
			<22779 23140 23394 16014 15536 16030>,
			<21131 23168 23663 18854 17765 18035>,
			<17066 23230 23830 22305 20673 20775>,
			<14726 23265 24088 23022 20906 21254>,
			<13612 23324 24442 23118 20315 21315>,
			<12990 23350 24593 23071 19950 21327>,
			<12860 23434 24126 22648 19847 21118>,
			<12794 23523 23548 22001 19719 20665>,
			<12788 22693 23522 21511 19181 19704>,
			<12951 19085 23740 21063 17793 17713>,
			<13163 16883 24078 20886 17137 16756>,
			<13272 17396 25051 21356 17266 16868>,
			<13348 18400 26043 22185 17549 17128>,
			<13463 19271 25813 22960 18177 17925>,
			<13706 20128 24507 23815 19559 19906>,
			<14003 20895 23421 24275 20860 21224>,
			<14287 21653 22793 24428 21967 21652>,
			<14580 22241 22276 24509 22915 22001>,
			<14746 21908 21846 24332 23569 22721>,
			<14833 19808 21486 23526 24104 23843>,
			<14886 17711 21054 22564 24252 24279>,
			<14610 16213 20370 21219 23347 23388>,
			<13716 15123 19829 20602 22826 22851>,
			<13410 14498 19418 21250 23370 23762>,
			<13284 14501 19417 20604 20082 20829>,
			<13053 13947 19642 21400 21200 18609>,
			<13010 14351 18165 19948 19137 16215>,
			<13364 13990 17233 19576 17462 15403>,
			<13276 14005 16420 19368 16719 15063>,
			<13418 14338 16511 19102 16103 14928>,
			<12244 14289 16353 19426 16857 15236>,
			<10988 13568 14827 20399 17761 15536>,
			<9765 10716 14308 20525 17721 15441>,
			<9053 9201 12933 21125 22352 19431>,
			<9053 9201 12933 21125 22352 19431>,
			<9053 9201 12933 21125 22352 19431>;
	};

	qcom,pc-temp-y6-lut {
		qcom,lut-col-legend = <(-10) 0 10 25 40 50>;
		qcom,lut-row-legend = <10000 9800 9600 9400 9200 9000>,
			<8800 8600 8400 8200 8000 7800>,
			<7600 7400 7200 7000 6800 6600>,
			<6400 6200 6000 5800 5600 5400>,
			<5200 5000 4800 4600 4400 4200>,
			<4000 3800 3600 3400 3200 3000>,
			<2800 2600 2400 2200 2000 1800>,
			<1600 1400 1200 1000 900 800>,
			<700 600 500 400 300 200>,
			<100 0>;
		qcom,lut-data = <5643 5296 5125 5022 4987 4978>,
			<5655 5308 5136 5022 4987 4979>,
			<5668 5318 5142 5023 4988 4981>,
			<5678 5326 5146 5023 4989 4982>,
			<5686 5331 5148 5024 4990 4983>,
			<5689 5333 5149 5024 4990 4984>,
			<5687 5331 5147 5024 4990 4984>,
			<5683 5327 5143 5024 4990 4984>,
			<5682 5324 5140 5024 4991 4984>,
			<5683 5320 5138 5024 4991 4985>,
			<5684 5318 5137 5025 4992 4985>,
			<5683 5319 5137 5026 4993 4986>,
			<5679 5320 5138 5027 4994 4986>,
			<5680 5324 5139 5029 4995 4987>,
			<5693 5333 5141 5031 4996 4988>,
			<5704 5340 5145 5034 4998 4989>,
			<5681 5343 5154 5038 5000 4991>,
			<5633 5345 5163 5043 5003 4993>,
			<5609 5340 5164 5050 5008 4997>,
			<5602 5311 5163 5060 5015 5002>,
			<5596 5284 5162 5066 5019 5005>,
			<5582 5269 5143 5055 5014 5002>,
			<5566 5257 5116 5038 5006 4997>,
			<5560 5250 5105 5028 4998 4991>,
			<5561 5244 5099 5019 4990 4983>,
			<5562 5241 5096 5016 4986 4980>,
			<5569 5238 5094 5016 4986 4980>,
			<5587 5237 5094 5017 4987 4980>,
			<5606 5236 5094 5017 4988 4980>,
			<5625 5237 5095 5019 4989 4981>,
			<5647 5238 5096 5021 4991 4982>,
			<5671 5246 5096 5023 4993 4985>,
			<5696 5261 5096 5026 4996 4988>,
			<5724 5277 5098 5027 4998 4991>,
			<5757 5295 5100 5029 5000 4993>,
			<5793 5316 5104 5029 5001 4995>,
			<5832 5342 5111 5026 4997 4991>,
			<5873 5370 5121 5022 4994 4986>,
			<5916 5396 5130 5022 4993 4986>,
			<5962 5422 5139 5022 4994 4990>,
			<6011 5450 5150 5023 4994 4993>,
			<6063 5480 5161 5026 4996 4995>,
			<6120 5515 5176 5029 4997 4995>,
			<6193 5559 5195 5030 4989 4982>,
			<6289 5622 5222 5032 4986 4978>,
			<6408 5683 5228 5034 4994 4991>,
			<6460 5745 5251 5039 5005 5003>,
			<6574 5819 5282 5050 5017 5016>,
			<6729 5927 5324 5063 5029 5026>,
			<7023 6083 5380 5072 5029 5024>,
			<7849 6331 5444 5064 5008 4999>,
			<9613 6990 5539 5054 5000 4994>,
			<14162 9394 5775 5071 5004 4998>,
			<29775 19182 6552 5096 5014 5005>,
			<29775 19182 6552 5096 5014 5005>,
			<29775 19182 6552 5096 5014 5005>;
	};

};
